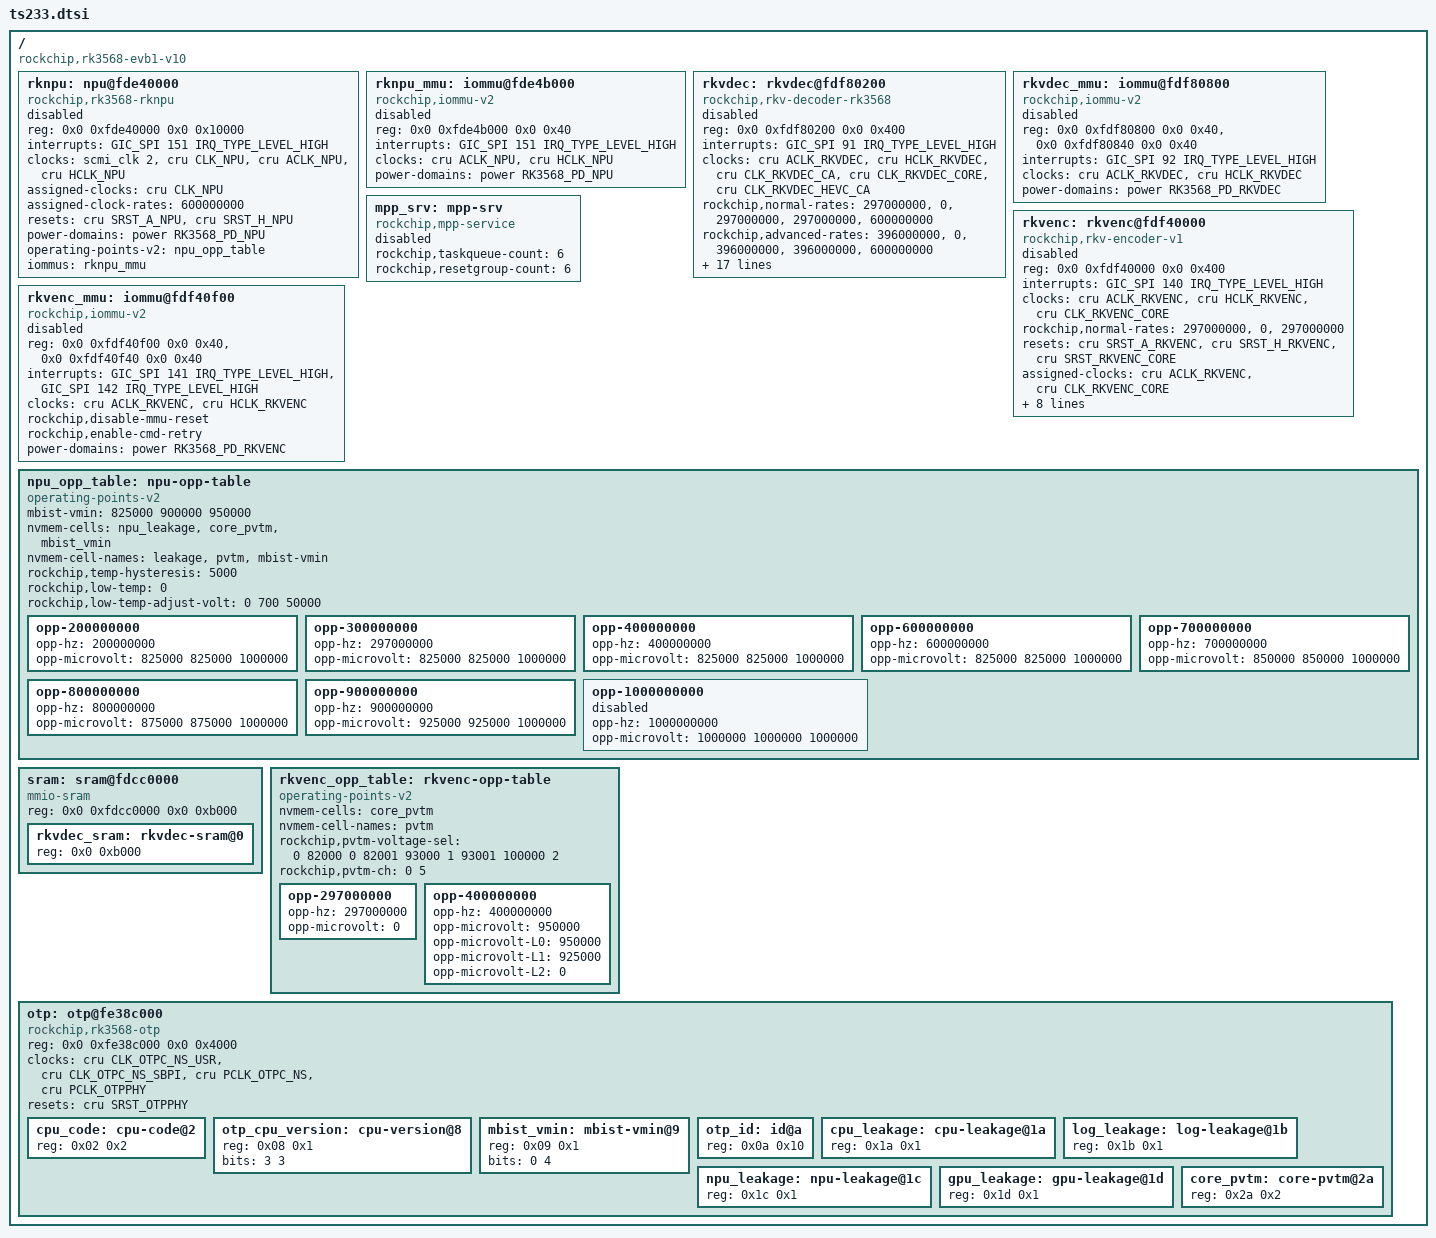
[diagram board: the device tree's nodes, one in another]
// SPDX-License-Identifier: (GPL-2.0+ OR MIT)
/*
 * Copyright (c) 2021 Rockchip Electronics Co., Ltd.
 *
 */

/dts-v1/;
#include "rk3568.dtsi"

/ {
	compatible = "rockchip,rk3568-evb1-v10", "rockchip,rk3568";
	rknpu: npu@fde40000 {
		compatible = "rockchip,rk3568-rknpu", "rockchip,rknpu";
		reg = <0x0 0xfde40000 0x0 0x10000>;
		interrupts = <GIC_SPI 151 IRQ_TYPE_LEVEL_HIGH>;
		clocks = <&scmi_clk 2>, <&cru CLK_NPU>, <&cru ACLK_NPU>, <&cru HCLK_NPU>;
		clock-names = "scmi_clk", "clk", "aclk", "hclk";
		assigned-clocks = <&cru CLK_NPU>;
		assigned-clock-rates = <600000000>;
		resets = <&cru SRST_A_NPU>, <&cru SRST_H_NPU>;
		reset-names = "srst_a", "srst_h";
		power-domains = <&power RK3568_PD_NPU>;
		operating-points-v2 = <&npu_opp_table>;
		iommus = <&rknpu_mmu>;
		status = "disabled";
	};
	 rknpu_mmu: iommu@fde4b000 {
		compatible = "rockchip,iommu-v2";
		reg = <0x0 0xfde4b000 0x0 0x40>;
		interrupts = <GIC_SPI 151 IRQ_TYPE_LEVEL_HIGH>;
		interrupt-names = "rknpu_mmu";
		clocks = <&cru ACLK_NPU>, <&cru HCLK_NPU>;
		clock-names = "aclk", "iface";
		power-domains = <&power RK3568_PD_NPU>;
		#iommu-cells = <0>;
		status = "disabled";
	};
	rkvdec: rkvdec@fdf80200 {
		compatible = "rockchip,rkv-decoder-rk3568", "rockchip,rkv-decoder-v2";
		reg = <0x0 0xfdf80200 0x0 0x400>;
		interrupts = <GIC_SPI 91 IRQ_TYPE_LEVEL_HIGH>;
		interrupt-names = "irq_dec";
		clocks = <&cru ACLK_RKVDEC>, <&cru HCLK_RKVDEC>, <&cru CLK_RKVDEC_CA>, <&cru CLK_RKVDEC_CORE>, <&cru CLK_RKVDEC_HEVC_CA>;
		clock-names = "aclk_vcodec", "hclk_vcodec","clk_cabac", "clk_core", "clk_hevc_cabac";
		rockchip,normal-rates = <297000000>, <0>, <297000000>, <297000000>, <600000000>;
		rockchip,advanced-rates = <396000000>, <0>, <396000000>, <396000000>, <600000000>;
		rockchip,default-max-load = <2088960>;
		resets = <&cru SRST_A_RKVDEC>, <&cru SRST_H_RKVDEC>, <&cru SRST_RKVDEC_CA>, <&cru SRST_RKVDEC_CORE>, <&cru SRST_RKVDEC_HEVC_CA>;
		assigned-clocks = <&cru ACLK_RKVDEC>, <&cru CLK_RKVDEC_CA>, <&cru CLK_RKVDEC_CORE>, <&cru CLK_RKVDEC_HEVC_CA>;
		assigned-clock-rates = <297000000>, <297000000>, <297000000>, <297000000>;
		reset-names = "video_a", "video_h", "video_cabac", "video_core", "video_hevc_cabac";
		power-domains = <&power RK3568_PD_RKVDEC>;
		iommus = <&rkvdec_mmu>;
		rockchip,srv = <&mpp_srv>;
		rockchip,taskqueue-node = <4>;
		rockchip,resetgroup-node = <4>;
		rockchip,sram = <&rkvdec_sram>;
		/* rcb_iova: start and size */
		rockchip,rcb-iova = <0x10000000 65536>;
		rockchip,rcb-min-width = <512>;
		status = "disabled";
	};
	rkvdec_mmu: iommu@fdf80800 {
		compatible = "rockchip,iommu-v2";
		reg = <0x0 0xfdf80800 0x0 0x40>, <0x0 0xfdf80840 0x0 0x40>;
		interrupts = <GIC_SPI 92 IRQ_TYPE_LEVEL_HIGH>;
		interrupt-names = "rkvdec_mmu";
		clocks = <&cru ACLK_RKVDEC>, <&cru HCLK_RKVDEC>;
		clock-names = "aclk", "iface";
		power-domains = <&power RK3568_PD_RKVDEC>;
		#iommu-cells = <0>;
		status = "disabled";
	};
	rkvenc: rkvenc@fdf40000 {
		compatible = "rockchip,rkv-encoder-v1";
		reg = <0x0 0xfdf40000 0x0 0x400>;
		interrupts = <GIC_SPI 140 IRQ_TYPE_LEVEL_HIGH>;
		interrupt-names = "irq_enc";
		clocks = <&cru ACLK_RKVENC>, <&cru HCLK_RKVENC>, <&cru CLK_RKVENC_CORE>;
		clock-names = "aclk_vcodec", "hclk_vcodec", "clk_core";
		rockchip,normal-rates = <297000000>, <0>, <297000000>;
		resets = <&cru SRST_A_RKVENC>, <&cru SRST_H_RKVENC>, <&cru SRST_RKVENC_CORE>;
		reset-names = "video_a", "video_h", "video_core";
		assigned-clocks = <&cru ACLK_RKVENC>, <&cru CLK_RKVENC_CORE>;
		assigned-clock-rates = <297000000>, <297000000>;
		iommus = <&rkvenc_mmu>;
		node-name = "rkvenc";
		rockchip,srv = <&mpp_srv>;
		rockchip,taskqueue-node = <3>;
		rockchip,resetgroup-node = <3>;
		power-domains = <&power RK3568_PD_RKVENC>;
		operating-points-v2 = <&rkvenc_opp_table>;
		status = "disabled";
	};

	rkvenc_mmu: iommu@fdf40f00 {
		compatible = "rockchip,iommu-v2";
		reg = <0x0 0xfdf40f00 0x0 0x40>, <0x0 0xfdf40f40 0x0 0x40>;
		interrupts = <GIC_SPI 141 IRQ_TYPE_LEVEL_HIGH>, <GIC_SPI 142 IRQ_TYPE_LEVEL_HIGH>;
		interrupt-names = "rkvenc_mmu0", "rkvenc_mmu1";
		clocks = <&cru ACLK_RKVENC>, <&cru HCLK_RKVENC>;
		clock-names = "aclk", "iface";
		rockchip,disable-mmu-reset;
		rockchip,enable-cmd-retry;
		#iommu-cells = <0>;
		power-domains = <&power RK3568_PD_RKVENC>;
		status = "disabled";
	};
	mpp_srv: mpp-srv {
		compatible = "rockchip,mpp-service";
		rockchip,taskqueue-count = <6>;
		rockchip,resetgroup-count = <6>;
		status = "disabled";
	};

	npu_opp_table: npu-opp-table {
		compatible = "operating-points-v2";
		mbist-vmin = <825000 900000 950000>;
		nvmem-cells = <&npu_leakage>, <&core_pvtm>, <&mbist_vmin>;
		nvmem-cell-names = "leakage", "pvtm", "mbist-vmin";
		rockchip,temp-hysteresis = <5000>;
		rockchip,low-temp = <0>;
		rockchip,low-temp-adjust-volt = <
				/* MHz    MHz    uV */
					0      700    50000
		>;

		opp-200000000 {
			opp-hz = /bits/ 64 <200000000>;
			opp-microvolt = <825000 825000 1000000>;
		};
		opp-300000000 {
			opp-hz = /bits/ 64 <297000000>;
			opp-microvolt = <825000 825000 1000000>;
		};
		opp-400000000 {
			opp-hz = /bits/ 64 <400000000>;
			opp-microvolt = <825000 825000 1000000>;
		};
		opp-600000000 {
			opp-hz = /bits/ 64 <600000000>;
			opp-microvolt = <825000 825000 1000000>;
		};
		opp-700000000 {
			opp-hz = /bits/ 64 <700000000>;
			opp-microvolt = <850000 850000 1000000>;
		};
		opp-800000000 {
			opp-hz = /bits/ 64 <800000000>;
			opp-microvolt = <875000 875000 1000000>;
		};
		opp-900000000 {
			opp-hz = /bits/ 64 <900000000>;
			opp-microvolt = <925000 925000 1000000>;
		};
		opp-1000000000 {
			opp-hz = /bits/ 64 <1000000000>;
			opp-microvolt = <1000000 1000000 1000000>;
			status = "disabled";
		};
	};
	sram: sram@fdcc0000 {
		compatible = "mmio-sram";
		reg = <0x0 0xfdcc0000 0x0 0xb000>;

		#address-cells = <1>;
		#size-cells = <1>;
		ranges = <0x0 0x0 0xfdcc0000 0xb000>;

		/* start address and size should be 4k algin */
		rkvdec_sram: rkvdec-sram@0 {
			reg = <0x0 0xb000>;
		};
 	};
	rkvenc_opp_table: rkvenc-opp-table {
		compatible = "operating-points-v2";

		nvmem-cells = <&core_pvtm>;
		nvmem-cell-names = "pvtm";
		rockchip,pvtm-voltage-sel = <
			0        82000   0
			82001    93000   1
			93001    100000  2
		>;
		rockchip,pvtm-ch = <0 5>;

		opp-297000000 {
			opp-hz = /bits/ 64 <297000000>;
			opp-microvolt = <0>;
		};
		opp-400000000 {
			opp-hz = /bits/ 64 <400000000>;
			opp-microvolt = <950000>;
			opp-microvolt-L0 = <950000>;
			opp-microvolt-L1 = <925000>;
			opp-microvolt-L2 = <0>;
		};
	};
	otp: otp@fe38c000 {
		compatible = "rockchip,rk3568-otp";
		reg = <0x0 0xfe38c000 0x0 0x4000>;
		#address-cells = <1>;
		#size-cells = <1>;
		clocks = <&cru CLK_OTPC_NS_USR>, <&cru CLK_OTPC_NS_SBPI>, <&cru PCLK_OTPC_NS>, <&cru PCLK_OTPPHY>;
		clock-names = "usr", "sbpi", "apb", "phy";
		resets = <&cru SRST_OTPPHY>;
		reset-names = "otp_phy";

		/* Data cells */
		cpu_code: cpu-code@2 {
			reg = <0x02 0x2>;
		};
		otp_cpu_version: cpu-version@8 {
			reg = <0x08 0x1>;
			bits = <3 3>;
		};
		mbist_vmin: mbist-vmin@9 {
			reg = <0x09 0x1>;
			bits = <0 4>;
		};
		otp_id: id@a {
			reg = <0x0a 0x10>;
		};
		cpu_leakage: cpu-leakage@1a {
			reg = <0x1a 0x1>;
		};
		log_leakage: log-leakage@1b {
			reg = <0x1b 0x1>;
		};
		npu_leakage: npu-leakage@1c {
			reg = <0x1c 0x1>;
		};
		gpu_leakage: gpu-leakage@1d {
			reg = <0x1d 0x1>;
		};
		core_pvtm:core-pvtm@2a {
			reg = <0x2a 0x2>;
		};
	};

};
